AUTOSAR XML (schema 00044)
package /ComponentTypes
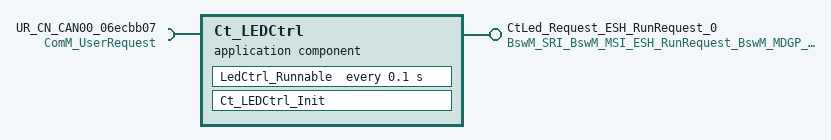
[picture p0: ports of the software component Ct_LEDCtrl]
  application sw component type Ct_LEDCtrl
    provide port CtLed_Request_ESH_RunRequest_0: nonqueued-sender-com-spec=requestedMode, provided-interface=BswM_SRI_BswM_MSI_ESH_RunRequest_BswM_MDGP_ESH_RunRequest
    require port UR_CN_CAN00_06ecbb07: required-com-specs=[RequestComMode, GetCurrentComMode, GetMaxComMode, GetRequestedComMode], required-interface=ComM_UserRequest
    behavior Ct_LEDCtrl_InternalBehavior
      timing event TMT_LedCtrl_Runnable: start-on-event=LedCtrl_Runnable, period=0.1
      init event Ct_LEDCtrl_InitEvent: start-on-event=Ct_LEDCtrl_Init
      runnable LedCtrl_Runnable
      runnable Ct_LEDCtrl_Init
        sync call SC_UR_CN_CAN00_06ecbb07_RequestComMode: operation=UR_CN_CAN00_06ecbb07.RequestComMode
  swc implementation Ct_LEDCtrl_Implementation: behavior=Ct_LEDCtrl_InternalBehavior
